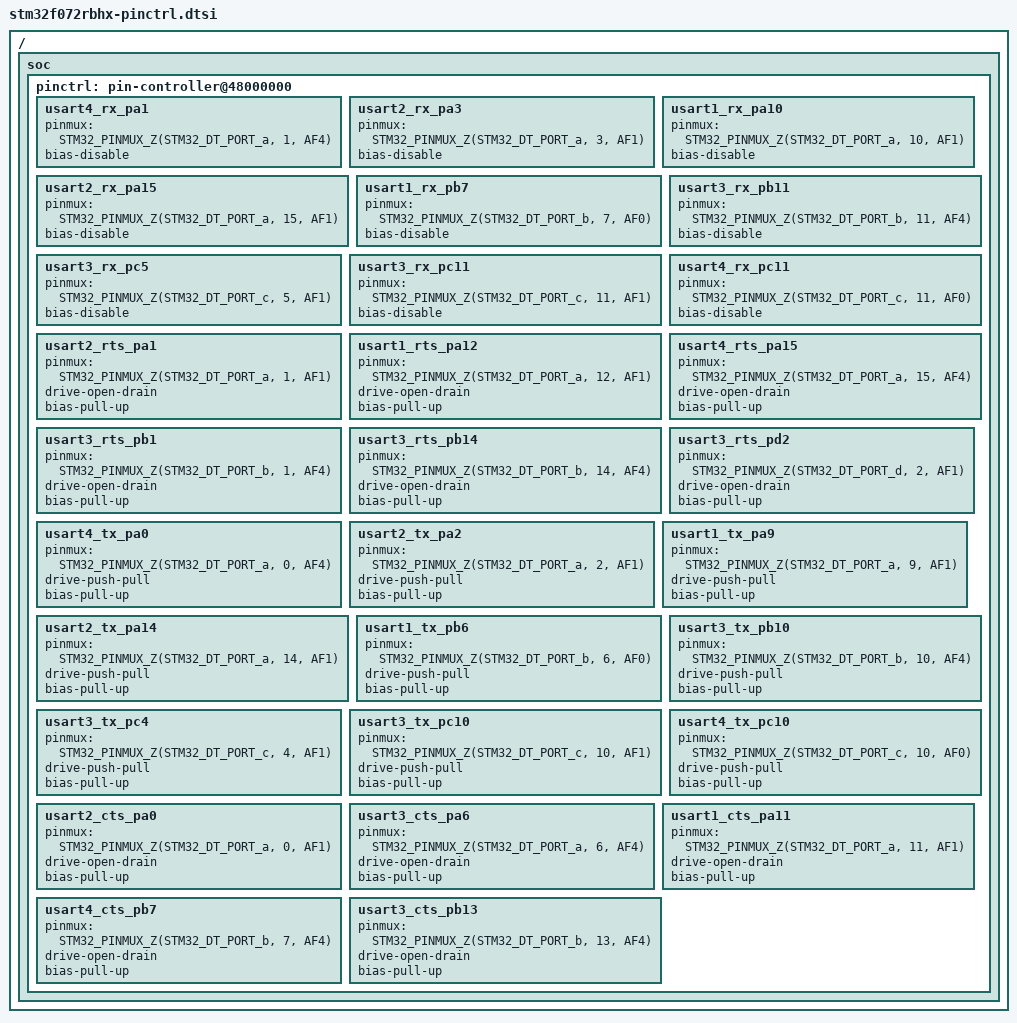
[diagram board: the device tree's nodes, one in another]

/*
 * NOTE: Autogenerated file using stm32_pinctrl_gen.py
 *
 * SPDX-License-Identifier: Apache-2.0
 */

#include <dt-bindings/pinctrl/stm32-pinctrl.h>

/ {
	soc {
		pinctrl: pin-controller@48000000 {
			/* UART_RX */
			usart4_rx_pa1: usart4_rx_pa1 {
				pinmux = <STM32_PINMUX_Z(STM32_DT_PORT_a, 1, AF4)>;
				bias-disable;
			};

			usart2_rx_pa3: usart2_rx_pa3 {
				pinmux = <STM32_PINMUX_Z(STM32_DT_PORT_a, 3, AF1)>;
				bias-disable;
			};

			usart1_rx_pa10: usart1_rx_pa10 {
				pinmux = <STM32_PINMUX_Z(STM32_DT_PORT_a, 10, AF1)>;
				bias-disable;
			};

			usart2_rx_pa15: usart2_rx_pa15 {
				pinmux = <STM32_PINMUX_Z(STM32_DT_PORT_a, 15, AF1)>;
				bias-disable;
			};

			usart1_rx_pb7: usart1_rx_pb7 {
				pinmux = <STM32_PINMUX_Z(STM32_DT_PORT_b, 7, AF0)>;
				bias-disable;
			};

			usart3_rx_pb11: usart3_rx_pb11 {
				pinmux = <STM32_PINMUX_Z(STM32_DT_PORT_b, 11, AF4)>;
				bias-disable;
			};

			usart3_rx_pc5: usart3_rx_pc5 {
				pinmux = <STM32_PINMUX_Z(STM32_DT_PORT_c, 5, AF1)>;
				bias-disable;
			};

			usart3_rx_pc11: usart3_rx_pc11 {
				pinmux = <STM32_PINMUX_Z(STM32_DT_PORT_c, 11, AF1)>;
				bias-disable;
			};

			usart4_rx_pc11: usart4_rx_pc11 {
				pinmux = <STM32_PINMUX_Z(STM32_DT_PORT_c, 11, AF0)>;
				bias-disable;
			};


			/* UART_RTS */
			usart2_rts_pa1: usart2_rts_pa1 {
				pinmux = <STM32_PINMUX_Z(STM32_DT_PORT_a, 1, AF1)>;
				drive-open-drain;
				bias-pull-up;
			};

			usart1_rts_pa12: usart1_rts_pa12 {
				pinmux = <STM32_PINMUX_Z(STM32_DT_PORT_a, 12, AF1)>;
				drive-open-drain;
				bias-pull-up;
			};

			usart4_rts_pa15: usart4_rts_pa15 {
				pinmux = <STM32_PINMUX_Z(STM32_DT_PORT_a, 15, AF4)>;
				drive-open-drain;
				bias-pull-up;
			};

			usart3_rts_pb1: usart3_rts_pb1 {
				pinmux = <STM32_PINMUX_Z(STM32_DT_PORT_b, 1, AF4)>;
				drive-open-drain;
				bias-pull-up;
			};

			usart3_rts_pb14: usart3_rts_pb14 {
				pinmux = <STM32_PINMUX_Z(STM32_DT_PORT_b, 14, AF4)>;
				drive-open-drain;
				bias-pull-up;
			};

			usart3_rts_pd2: usart3_rts_pd2 {
				pinmux = <STM32_PINMUX_Z(STM32_DT_PORT_d, 2, AF1)>;
				drive-open-drain;
				bias-pull-up;
			};


			/* UART_TX */
			usart4_tx_pa0: usart4_tx_pa0 {
				pinmux = <STM32_PINMUX_Z(STM32_DT_PORT_a, 0, AF4)>;
				drive-push-pull;
				bias-pull-up;
			};

			usart2_tx_pa2: usart2_tx_pa2 {
				pinmux = <STM32_PINMUX_Z(STM32_DT_PORT_a, 2, AF1)>;
				drive-push-pull;
				bias-pull-up;
			};

			usart1_tx_pa9: usart1_tx_pa9 {
				pinmux = <STM32_PINMUX_Z(STM32_DT_PORT_a, 9, AF1)>;
				drive-push-pull;
				bias-pull-up;
			};

			usart2_tx_pa14: usart2_tx_pa14 {
				pinmux = <STM32_PINMUX_Z(STM32_DT_PORT_a, 14, AF1)>;
				drive-push-pull;
				bias-pull-up;
			};

			usart1_tx_pb6: usart1_tx_pb6 {
				pinmux = <STM32_PINMUX_Z(STM32_DT_PORT_b, 6, AF0)>;
				drive-push-pull;
				bias-pull-up;
			};

			usart3_tx_pb10: usart3_tx_pb10 {
				pinmux = <STM32_PINMUX_Z(STM32_DT_PORT_b, 10, AF4)>;
				drive-push-pull;
				bias-pull-up;
			};

			usart3_tx_pc4: usart3_tx_pc4 {
				pinmux = <STM32_PINMUX_Z(STM32_DT_PORT_c, 4, AF1)>;
				drive-push-pull;
				bias-pull-up;
			};

			usart3_tx_pc10: usart3_tx_pc10 {
				pinmux = <STM32_PINMUX_Z(STM32_DT_PORT_c, 10, AF1)>;
				drive-push-pull;
				bias-pull-up;
			};

			usart4_tx_pc10: usart4_tx_pc10 {
				pinmux = <STM32_PINMUX_Z(STM32_DT_PORT_c, 10, AF0)>;
				drive-push-pull;
				bias-pull-up;
			};


			/* UART_CTS */
			usart2_cts_pa0: usart2_cts_pa0 {
				pinmux = <STM32_PINMUX_Z(STM32_DT_PORT_a, 0, AF1)>;
				drive-open-drain;
				bias-pull-up;
			};

			usart3_cts_pa6: usart3_cts_pa6 {
				pinmux = <STM32_PINMUX_Z(STM32_DT_PORT_a, 6, AF4)>;
				drive-open-drain;
				bias-pull-up;
			};

			usart1_cts_pa11: usart1_cts_pa11 {
				pinmux = <STM32_PINMUX_Z(STM32_DT_PORT_a, 11, AF1)>;
				drive-open-drain;
				bias-pull-up;
			};

			usart4_cts_pb7: usart4_cts_pb7 {
				pinmux = <STM32_PINMUX_Z(STM32_DT_PORT_b, 7, AF4)>;
				drive-open-drain;
				bias-pull-up;
			};

			usart3_cts_pb13: usart3_cts_pb13 {
				pinmux = <STM32_PINMUX_Z(STM32_DT_PORT_b, 13, AF4)>;
				drive-open-drain;
				bias-pull-up;
			};

		};
	};
};
